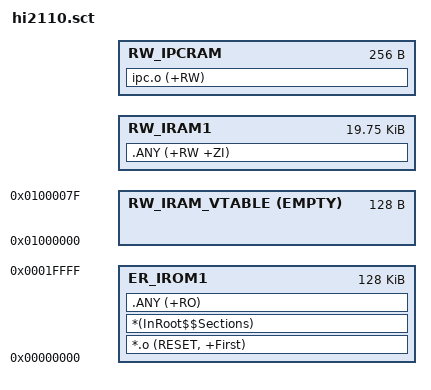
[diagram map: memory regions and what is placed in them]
LR_IROM1 0x00000000 0x20000 {
  ER_IROM1 0x00000000 0x20000  {
   *.o (RESET, +First)
   *(InRoot$$Sections)
   .ANY (+RO)
  }
  RW_IRAM_VTABLE 0x01000000 EMPTY 128  {
  }
  RW_IRAM1 +0 (0x5000 - 256)  {
   .ANY (+RW +ZI)
  }
  RW_IPCRAM +0 256 {
   ipc.o (+RW)
  }
}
